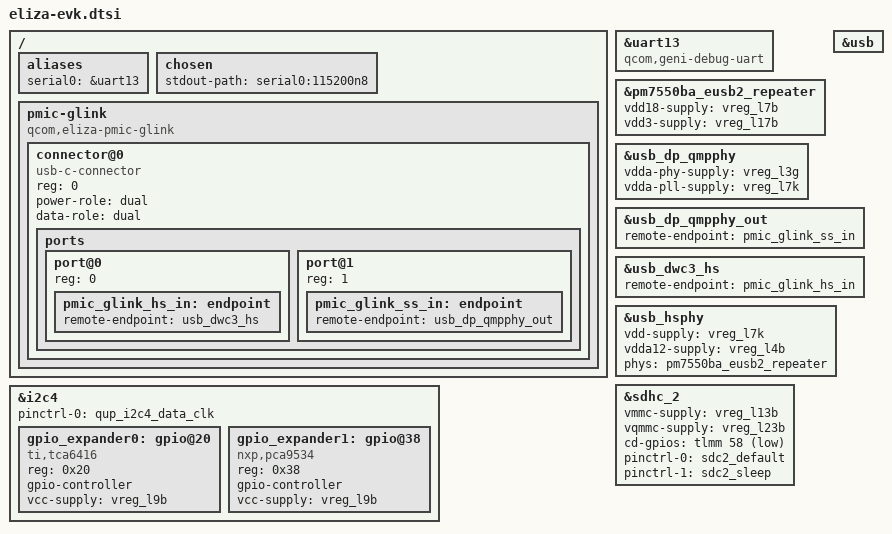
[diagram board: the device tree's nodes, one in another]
// SPDX-License-Identifier: BSD-3-Clause
/*
 * Copyright (c) Qualcomm Technologies, Inc. and/or its subsidiaries.
 */

/ {
	aliases {
		serial0 = &uart13;
	};

	chosen {
		stdout-path = "serial0:115200n8";
	};

	pmic-glink {
		compatible = "qcom,eliza-pmic-glink",
			     "qcom,sm8550-pmic-glink",
			     "qcom,pmic-glink";
		#address-cells = <1>;
		#size-cells = <0>;

		connector@0 {
			compatible = "usb-c-connector";
			reg = <0>;

			power-role = "dual";
			data-role = "dual";

			ports {
				#address-cells = <1>;
				#size-cells = <0>;

				port@0 {
					reg = <0>;

					pmic_glink_hs_in: endpoint {
						remote-endpoint = <&usb_dwc3_hs>;
					};
				};

				port@1 {
					reg = <1>;

					pmic_glink_ss_in: endpoint {
						remote-endpoint = <&usb_dp_qmpphy_out>;
					};
				};
			};
		};
	};
};

&uart13 {
	compatible = "qcom,geni-debug-uart";

	status = "okay";
};

&pm7550ba_eusb2_repeater {
	vdd18-supply = <&vreg_l7b>;
	vdd3-supply = <&vreg_l17b>;
};

&usb {
	status = "okay";
};

&usb_dp_qmpphy {
	vdda-phy-supply = <&vreg_l3g>;
	vdda-pll-supply = <&vreg_l7k>;

	status = "okay";
};

&usb_dp_qmpphy_out {
	remote-endpoint = <&pmic_glink_ss_in>;
};

&usb_dwc3_hs {
	remote-endpoint = <&pmic_glink_hs_in>;
};

&usb_hsphy {
	vdd-supply = <&vreg_l7k>;
	vdda12-supply = <&vreg_l4b>;

	phys = <&pm7550ba_eusb2_repeater>;

	status = "okay";
};

&sdhc_2 {
	vmmc-supply = <&vreg_l13b>;
	vqmmc-supply = <&vreg_l23b>;

	cd-gpios = <&tlmm 58 GPIO_ACTIVE_LOW>;

	pinctrl-0 = <&sdc2_default>;
	pinctrl-1 = <&sdc2_sleep>;
	pinctrl-names = "default", "sleep";

	status = "okay";
};

&i2c4 {
	pinctrl-0 = <&qup_i2c4_data_clk>;
	pinctrl-names = "default";

	status = "okay";

	gpio_expander0: gpio@20 {
		compatible = "ti,tca6416";
		reg = <0x20>;

		gpio-controller;
		#gpio-cells = <2>;

		vcc-supply = <&vreg_l9b>;
	};

	gpio_expander1: gpio@38 {
		compatible = "nxp,pca9534";
		reg = <0x38>;

		gpio-controller;
		#gpio-cells = <2>;

		vcc-supply = <&vreg_l9b>;
	};
};
